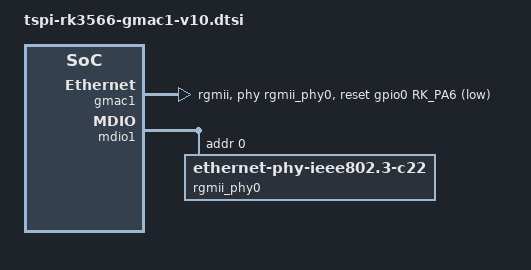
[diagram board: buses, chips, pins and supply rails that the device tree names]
/********************************************************************
 * 共建开源生态是我们的目标。为此我们努力把性价比和颜值做到极致。
 * 同时全面开放SDK、原理图、PCB等所有软硬件资料。
 * 提供交流平台、免费训练营、开发者扶持计划等，让您能够尽情发挥您的才华。
 * 我们坚信自由和定制化是开源生态的核心。
 * 泰山派开发板不仅仅是立创开发板的产品，它更是我们共同努力的成果。
 * 我们只是抛砖引玉，期望能够激发出更多的创意和想法。
 * 我们渴望与志同道合的伙伴们携手合作，共同探索无限可能。
 * 让我们各展所长，共同建设一个强大的开源生态系统。
 * 泰山派开发板等待着您的加入。
 * 让我们一起推动技术的前进，一起创未来！
 *********************************************************************
 * 立创开发板不靠卖板赚钱，以培养中国工程师为己任。  
 * 开发板官网：www.lckfb.com
 * 嘉立创论坛：www.jlc-bbs.com/lckfb 
 * 资料教程：wiki.lckfb.com  
 * 开源项目：https://oshwhub.com/search?wd=%E6%B3%B0%E5%B1%B1%E6%B4%BE   
 * 关注B站：【立创开发板】，掌握我们的最新动态！  
 *********************************************************************/

&gmac1 {
	phy-mode = "rgmii";
	clock_in_out = "output";

	snps,reset-gpio = <&gpio0 RK_PA6 GPIO_ACTIVE_LOW>;
	snps,reset-active-low;
	/* Reset time is 20ms, 100ms for rtl8211f */
	snps,reset-delays-us = <0 20000 100000>;

	/* Use 100Mbps negotiation */
	// max-speed = <100>;

	assigned-clocks = <&cru SCLK_GMAC1_RX_TX>, <&cru SCLK_GMAC1>;
	assigned-clock-parents = <&cru SCLK_GMAC1_RGMII_SPEED>, <&cru CLK_MAC1_2TOP>;
	assigned-clock-rates = <0>, <125000000>;

	pinctrl-names = "default";
	pinctrl-0 = <&gmac1m1_miim
		     &gmac1m1_tx_bus2
		     &gmac1m1_rx_bus2
		     &gmac1m1_rgmii_clk
		     &gmac1m1_rgmii_bus>;

	tx_delay = <0x36>;
	rx_delay = <0x25>;

	phy-handle = <&rgmii_phy0>;
	status = "okay";
};

&mdio1 {
	rgmii_phy0: phy@0 {
		compatible = "ethernet-phy-ieee802.3-c22";
		reg = <0x0>;
	};
};
